# nrf7140_wificore register map
Vendor: Nordic Semiconductor; Series: nRF71; File version: 1
Registers are 32-bit, read-write, reset 0x0 unless marked. A register's access mark holds for its fields unless they carry their own. Offsets are from the block's base; [hi:lo] are bit positions; lines under a group give offsets from that group; {n}, {i} and the like mark numbered series; 'fields as' and 'values as' point back to an identical list.

## RPUPHY (part 8 of 8) — WIFICore RPU PHY peripherals
Base 0x48080000; alternate view of RPUMAC
0x14000 WLAN_RXP group — Unspecified
  0x00 RESET — WLAN RXP RESET
    [2] WLANRXPSTATSCOUNTERSRESET — Self-clearing software reset for the statistics counters.
    [1] WLANRXPLATCHEDSOFTWARERESET — Latched software reset.
    [0] WLANRXPPULSEDSOFTWARERESET — Self-clearing software reset.
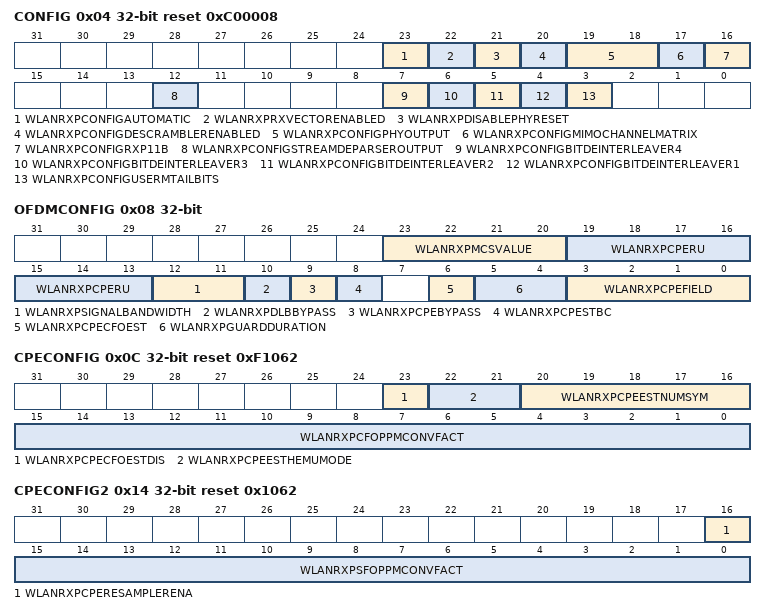
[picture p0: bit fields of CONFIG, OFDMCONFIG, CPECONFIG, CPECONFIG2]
  0x04 CONFIG reset 0xC00008 — WLAN RXP CONFIG
    [23] WLANRXPCONFIGAUTOMATIC — Enable automatic configuration of the RXP.
      0=Manual configuration mode; 1=Automatic configuration mode
    [22] WLANRXPRXVECTORENABLED — Enable Rx-vector generation.
      0=Rx-vector not generated; 1=Rx-vector is sent before the decoded data
    [21] WLANRXPDISABLEPHYRESET — Disable automatic PHY reset.
      0=PHY will automatically reset; 1=PHY will not automatically reset
    [20] WLANRXPCONFIGDESCRAMBLERENABLED — Enable descrambler.
      0=BypassDescrambler; 1=EnableDescrambler
    [19:18] WLANRXPCONFIGPHYOUTPUT — Select PHY output.
      0=Viterbi decoder (1 encoder stream, chain 1); 1=ViterbiDecoder1Enco1 (Viterbi decoder (1 encoder stream, chain 2)); 2=Viterbi decoder (2 encoder streams); 3=LdpcDecoder
    [17] WLANRXPCONFIGMIMOCHANNELMATRIX — Select MIMO decoder channel matrix TBus write port destination.
      0=MimoDecoder; 1=LdpcDecoder
    [16] WLANRXPCONFIGRXP11B — Select 802.11b RX demodulator.
      0=OfdmDemodulator; 1=80211BDemodulator
    [12] WLANRXPCONFIGSTREAMDEPARSEROUTPUT — Route first stream deparser output stream to either TBus port or LDPC block formation unit.
      0=Route output data to TBus port; 1=Route output data to LDPC block formation unit
    [7] WLANRXPCONFIGBITDEINTERLEAVER4 — Configure bit de-interleaver for fourth spatial stream.
      0=Bypass bit de-interleaver; 1=UseBitDeInterleaver
    [6] WLANRXPCONFIGBITDEINTERLEAVER3 — Configure bit de-interleaver for third spatial stream.
      0=Bypass bit de-interleaver; 1=UseBitDeInterleaver
    [5] WLANRXPCONFIGBITDEINTERLEAVER2 — Configure bit de-interleaver for second spatial stream.
      0=Bypass bit de-interleaver; 1=UseBitDeInterleaver
    [4] WLANRXPCONFIGBITDEINTERLEAVER1 — Configure bit de-interleaver for first spatial stream.
      0=Bypass bit de-interleaver; 1=UseBitDeInterleaver
    [3] WLANRXPCONFIGUSERMTAILBITS — Configure the removal of tail bits at the output of the Viterbi
      0=NeverRemoveTailBits; 1=Remove tail bits at the output of Viterbi during DATA decoding (cfg_dec_field = 0)
  0x08 OFDMCONFIG — WLAN RXP OFDM CONFIG
    [23:20] WLANRXPMCSVALUE — Modulation and coding scheme
    [19:13] WLANRXPCPERU — HE resource unit allocation for CPE module
    [12:11] WLANRXPSIGNALBANDWIDTH — Selects the signal bandwidth0 : 20MHz1 : 40MHz2 : 80MHz3 : reservedMust be equal or less than CHANNEL_BANDWIDTH.For receive, see the OPERATING_WINDOW description.For transmit, when signal bandwidth is less than channel bandwidth, input OFDM symbol will be duplicatedbefore performing inverse FFT. If channel bandwidth is two times signal bandwidth then OFDM symbol will beduplicated and if channel bandwidth is four times signal bandwidth then OFDM symbol will be quadrupled.
    [10] WLANRXPDLBBYPASS — Delay buffer bypass
      0=DlbEnabled; 1=DlbBypassed
    [9] WLANRXPCPEBYPASS — CPE compensation control.0 : CPE compensation1 : BypassThis field is used when REMOVE_SUB_CARRIERS is active (RX mode).In both cases pilots will be discarded but when bypass is not activeCPE compensation will be performed.
    [8] WLANRXPCPESTBC — Selects STBC mode. HT-packets only.
      0=NonStbc; 1=Stbc
    [6] WLANRXPCPECFOEST — When set enables the CFO estimation based on the CPE.
    [5:4] WLANRXPGUARDDURATION — Specifies the guard duration to be inserted or removed:
      0=04Us; 1=08Us; 2=16Us; 3=32Us
    [3:0] WLANRXPCPEFIELD — Selects packet type:0: LSIG (L)1: LDATA (L)2: HTSIG (L)3: HTDATA (HT)4: VHTSIGA (L)5: VHTSIGB (HT)6: VHTDATA (VHT)7: RLSIG (L)8: HESIGA_SU (HT)9: HESIGA_X (HT)10 : HESIGA_ER (HT)11 : HESIGA_MU (HT)12 : HESIGB (VHT)13 : HEDATA_SU (HE)14 : HEDATA_ER (HE)15 : HEDATA_MU (HE)Packet types 0-3 (Legacy, HT_MF, HT_GF, VHT) are in Pre-HE group with OFDM symbol length of 3.2us.HE packet has 12.8us OFDM symbol length.NOTE: Whenever field is configured the initial state of scrambler will be set accordingly.Scrambler is used within CPE block to generate PN sequence for pilot sign generation. PN sequencehas 127 elements and cyclically repeats after 127 OFDM symbols.
  0x0C CPECONFIG reset 0xF1062 — WLAN RXP CPE CONFIG
    [23] WLANRXPCPECFOESTDIS — Disable the CFO estimation based on the CPE : ignore RXP_CPE_CFO_EST field
    [22:21] WLANRXPCPEESTHEMUMODE — CPE based frequency offset estimation mode for HE-MU packets:
      0=Use HE-SIG-B and Data symbols CPE estimations (final HE-SIG-B in ppm is sum to the Data ppm estimations); 1=Use HE-SIG-B symbols CPE estimations only; 2=Use Data symbols CPE estimations only (if there is only one data Symbol then the HE-SIG-B is used)
    [20:16] WLANRXPCPEESTNUMSYM — Number of CPE estimations used for the CPE based frequency offset estimation.
    [15:0] WLANRXPCFOPPMCONVFACT — Carrier Frequency Offset, to PPM conversion factor: value of OpBW/fc,where OpBw is the operating bandwidth and fc is the channel centre frequency. (u-4.20)Note: default value set for OpBW = 20MHz and fc = 5GHz
  0x10 CPESTATUS ro — WLAN RXP CPE STATUS
    [15:0] WLANRXPCPEFREQUENCYOFFSET — CPE based frequency offset estimation (s-5.20).
  0x14 CPECONFIG2 reset 0x1062 — WLAN RXP CPE CONFIG 2
    [16] WLANRXPCPERESAMPLERENA — Enable CPE estimation based SFO error update to the SCP resampler.
    [15:0] WLANRXPSFOPPMCONVFACT — Sampling Frequency Offset, time tracking conversion factor: value of [resampler factor] * OpBW/fc,where OpBw is the operating bandwidth and fc is the channel centre frequency. (u-4.20)Note: default value set for resampler factor = 1, OpBW = 20MHz and fc = 5GHz
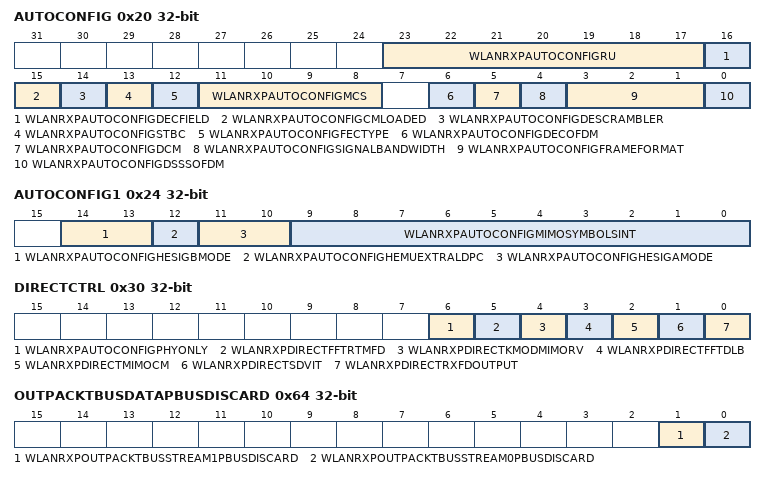
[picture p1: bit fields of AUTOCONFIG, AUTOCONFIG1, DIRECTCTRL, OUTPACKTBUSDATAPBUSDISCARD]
  0x20 AUTOCONFIG — WLAN RXP AUTO CONFIG
    [23:17] WLANRXPAUTOCONFIGRU — HE resource unit allocation
    [16] WLANRXPAUTOCONFIGDECFIELD — Identifies the type of field to be decoded
      0=Data - decoded data sent to EDC; 1=Header - decoded data sent to receiver training mode
    [15] WLANRXPAUTOCONFIGCMLOADED — Assume channel matrices are already loaded into the MIMO decoder
      0=Don't assume channel matrices have been loaded; 1=Assume channel matrices have been loaded
    [14] WLANRXPAUTOCONFIGDESCRAMBLER — Descrambler mode
      0=DescramblerDisabled; 1=DescramblerEnabled
    [13] WLANRXPAUTOCONFIGSTBC — STBC mode
      0=StbcModeDisabled; 1=StbcModeEnabled
    [12] WLANRXPAUTOCONFIGFECTYPE — FEC type
      0=Bcc; 1=Ldpc
    [11:8] WLANRXPAUTOCONFIGMCS — MCSLegacy-0: BPSK rate 1/2Legacy-1: BPSK rate 3/4Legacy-2: QPSK rate 1/2Legacy-3: QPSK rate 3/4Legacy-4: 16-QAM rate 1/2Legacy-5: 16-QAM rate 3/4Legacy-6: 64-QAM rate 2/3Legacy-7: 64-QAM rate 3/4HT-0: BPSK rate 1/2HT-1: QPSK rate 1/2HT-2: QPSK rate 3/4HT-3: 16-QAM rate 1/2HT-4: 16-QAM rate 3/4HT-5: 64-QAM rate 2/3HT-6: 64-QAM rate 3/4HT-7: 64-QAM rate 5/6VHT-0: BPSK rate 1/2VHT-1: QPSK rate 1/2VHT-2: QPSK rate 3/4VHT-3: 16-QAM rate 1/2VHT-4: 16-QAM rate 3/4VHT-5: 64-QAM rate 2/3VHT-6: 64-QAM rate 3/4VHT-7: 64-QAM rate 5/6VHT-8: 256-QAM rate 3/4VHT-9: 256-QAM rate 5/6HE-0: BPSK rate 1/2HE-1: QPSK rate 1/2HE-2: QPSK rate 3/4HE-3: 16-QAM rate 1/2HE-4: 16-QAM rate 3/4HE-5: 64-QAM rate 2/3HE-6: 64-QAM rate 3/4HE-7: 64-QAM rate 5/6HE-8: 256-QAM rate 3/4HE-9: 256-QAM rate 5/6HE-10: 1024-QAM rate 3/4HE-11: 1024-QAM rate 5/6
    [6] WLANRXPAUTOCONFIGDECOFDM — Decode OFDM data (output MUX selection)
      0=OutputDsss11BData; 1=OutputOfdmData
    [5] WLANRXPAUTOCONFIGDCM — Dual carrier modulation
      0=DcmDisabled; 1=DcmEnabled
    [4] WLANRXPAUTOCONFIGSIGNALBANDWIDTH — Signal bandwidth
      0=20Mhz; 1=40Mhz
    [3:1] WLANRXPAUTOCONFIGFRAMEFORMAT — Frame format
      0=Legacy; 1=HtMf; 2=HtGf; 3=HeTb; 4=HeSu; 5=HeMu; 6=HeEr
    [0] WLANRXPAUTOCONFIGDSSSOFDM — DSSS or OFDM
      0=Dsss; 1=Ofdm
  0x24 AUTOCONFIG1 — WLAN RXP AUTO CONFIG 1
    [14:13] WLANRXPAUTOCONFIGHESIGBMODE — Indicates if HE-SIG-B is being decoded and its format:
      0=NormalVhtPacket; 1=HE-SIG-B uncompressed 20/40 MHz ppduBW (18-bit common field, 52-bit User block field); 2=HeSigBUncompressed2 (HE-SIG-B uncompressed 80 MHz ppduBw (27-bit common field,52-bit User block field)); 3=HE-SIG-B compressed (no common field, 52-bit User block field)
    [12] WLANRXPAUTOCONFIGHEMUEXTRALDPC — Force LDPC extra segment flag for decoder configuration for HE-MU packet decoding.
    [11:10] WLANRXPAUTOCONFIGHESIGAMODE — Determines the state of HE-SIGA decoding, used in the LLR combining process
      0=HE-SU - Default state, assumes packet is HE-SU (or any non-HE packet), but may be determined as non HE-SU after decoding LSIG; 1=X - Intermediate state before determining packet is either HE-MU or HE-ER; 2=HE-MU - Packet determined as HE-MU; 3=HE-ER - Packet determined as HE-ER
    [9:0] WLANRXPAUTOCONFIGMIMOSYMBOLSINT — Number of OFDM symbols for which the channel matrices are valid for the MIMO decoder. When this register is set to zero, the channel matrices will never be invalidated.
  0x28 AUTOCONFIG2 — WLAN RXP AUTO CONFIG 2
    [23:0] WLANRXPAUTOCONFIGNUMCODEDBITS — Number of coded bits.For BCC this is per encoded stream and includes service and tail bits.For LDPC this includes service bits.
  0x2C AUTOCONFIG3 — WLAN RXP AUTO CONFIG 3
    [23:0] WLANRXPAUTOCONFIGNUMOFDMSYM — Number of OFDM symbols.Only used in BCC mode.When non-zero, the RXP output packer flushes LLRs to the Viterbi decoder at the end of the last OFDM symbol.
  0x30 DIRECTCTRL — WLAN RXP DIRECT CTRL
    [6] WLANRXPAUTOCONFIGPHYONLY — Defines auto-configuration for WLAN_RXP_DIRECT_RXFD_OUTPUT:
      0=RXP output goes to next pipeline stage (i.e. MAC).; 1=RXP output goes to EDC (tbus)
    [5] WLANRXPDIRECTFFTRTMFD — Selects direct or EDC (tbus) connections.
      0=Tbus; 1=Direct
    [4] WLANRXPDIRECTKMODMIMORV — Selects direct or EDC (tbus) connections.
      0=Tbus; 1=Direct
    [3] WLANRXPDIRECTFFTDLB — Selects direct or EDC (tbus) connections.
      0=Tbus; 1=Direct
    [2] WLANRXPDIRECTMIMOCM — Selects direct or EDC (tbus) connections.
      0=Tbus; 1=Direct
    [1] WLANRXPDIRECTSDVIT — Selects direct or EDC (tbus) connections.
      0=Tbus; 1=Direct
    [0] WLANRXPDIRECTRXFDOUTPUT — Selects whether TXP input comes from previous pipeline stage or EDC (tbus).
      0=Tbus; 1=Direct
  0x34 AUTOCONFIG4 — WLAN RXP AUTO CONFIG 4
    [12:0] WLANRXPAUTOCONFIGHENCBPSLAST — Number of coded bits per symbols in the last pair of OFDM symbols for HE and STBC.
  0x50 STATSCOUNTER0 — WLAN RXP STATS COUNTER 0
    [23:0] WLANRXPGENERATEDEOPCOUNT — Number of decoded packets based on the EOP flag.
  0x64 OUTPACKTBUSDATAPBUSDISCARD — WLAN RXP OUTPACK TBUS DATA PBUS DISCARD
    [1] WLANRXPOUTPACKTBUSSTREAM1PBUSDISCARD — Set this register to '1' to discard the output from the T-Bus Read component that routes data from the stream 1 path to the T-Bus.
    [0] WLANRXPOUTPACKTBUSSTREAM0PBUSDISCARD — Set this register to '1' to discard the output from the T-Bus Read component that routes data from the stream 0 path to the T-Bus.
  {0x70+4j} CPECHSTREAM1PILOT[{j}] (j=0..7) — Description collection: WLAN RXP CPE CH STREAM1 PILOT
    [23:0] WLANCPECHSTREAM1PILOT — Channel estimate for stream 1 on the pilot subcarrier.
  {0x90+4j} CPECHSTREAM2PILOT[{j}] (j=0..7) — Description collection: WLAN RXP CPE CH STREAM2 PILOT
    [23:0] WLANCPECHSTREAM2PILOT — Channel estimate for stream 2 on the pilot subcarrier.
  0xB4 WLANRXFDDEBUG
    [1:0] WLANRXFDDEBUG — Enable debug registers WLAN_RXFD_DEBUG_VALID and WLAN_RXFD_DEBUG_ENABLE
      0=Disabled; 1=ValidEnable; 2=Sticky(Valid), Sticky(Enable); 3=Valid & Enable, Sticky(Valid & Enable)
  0xB8 WLANRXFDDEBUGVALID ro
    [31:0] WLANRXFDDEBUGVALID — Live state of the valid flow control signals0: DBL Input1: DLB Output2: CPE/KMOD Input3: CPE/KMOD Output4: MIMO RV Input5: MIMO CM Input6: MIMO Output7: DCM Input8: DCM Output9: BDI Input10: BDI Output11: LLR Combining BDI Input12: LLR Combining DCM Input13: LLR Combining Output14: Deparser Input15: Deparser Output16: OutputPacker Input17: OutputPacker Output18: Viterbi Input19: Viterbi Output20: LDPC Input21: LDPC Output22: Descramler Input23: Descrambler Output24: Error Mask Input25: Error Mask Output26: RTM FD FFT Raw Input27: RTM FD Dec Input28: RTM FD RXV Output29: RTM FD BMF Output30: RTM FD RTM CM Output31: RTM FD CHE Output
  0xBC WLANRXFDDEBUGENABLE ro
    [31:0] WLANRXFDDEBUGENABLE — Live state of the enable flow control signals0: DBL Input1: DLB Output2: CPE/KMOD Input3: CPE/KMOD Output4: MIMO RV Input5: MIMO CM Input6: MIMO Output7: DCM Input8: DCM Output9: BDI Input10: BDI Output11: LLR Combining BDI Input12: LLR Combining DCM Input13: LLR Combining Output14: Deparser Input15: Deparser Output16: OutputPacker Input17: OutputPacker Output18: Viterbi Input19: Viterbi Output20: LDPC Input21: LDPC Output22: Descramler Input23: Descrambler Output24: Error Mask Input25: Error Mask Output26: RTM FD FFT Raw Input27: RTM FD Dec Input28: RTM FD RXV Output29: RTM FD BMF Output30: RTM FD RTM CM Output31: RTM FD CHE Output
0x15000 WLAN_RXP_11B group — Unspecified
  0x00 RESET — WLAN RXP 11B RESET
    [2] WLANRXP11BSTATSCOUNTERSRESET — Self-clearing software reset for the statistics counters.
    [1] WLANRXP11BLATCHEDSOFTWARERESET — Latched software reset.
    [0] WLANRXP11BPULSEDSOFTWARERESET — Self-clearing software reset.
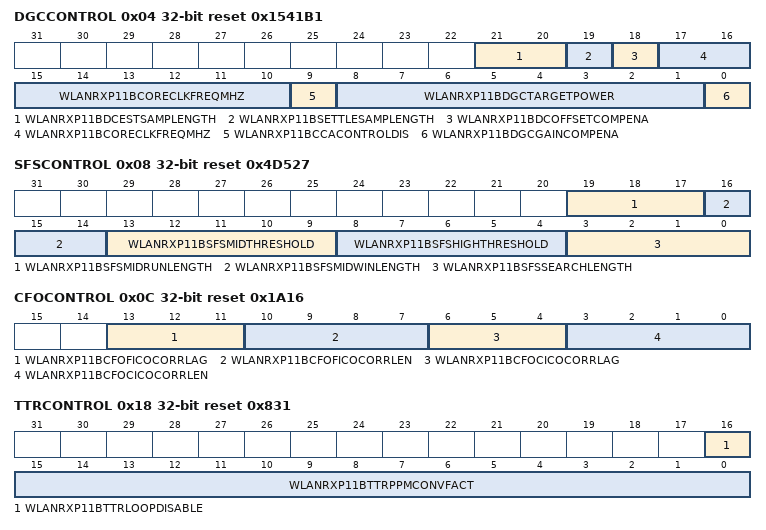
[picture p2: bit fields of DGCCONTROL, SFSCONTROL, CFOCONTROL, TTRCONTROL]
  0x04 DGCCONTROL reset 0x1541B1 — WLAN RXP 11B DGC CONTROL
    [21:20] WLANRXP11BDCESTSAMPLENGTH — Number of samples used for DC estimation:
      0=44Samples; 1=88Samples; 2=132Samples; 3=176Samples
    [19] WLANRXP11BSETTLESAMPLENGTH — Number of samples for datapath settling before DC estimation starts:
      0=22Samples; 1=44Samples
    [18] WLANRXP11BDCOFFSETCOMPENA — Enable/disable DC offset compensation.
    [17:10] WLANRXP11BCORECLKFREQMHZ — Core clock frequency in MHz. (u8.0)
    [9] WLANRXP11BCCACONTROLDIS — Disable / enable CCA control for correlation indication and status known (ED).Timer non-zero flag always zero when disabled.
    [8:1] WLANRXP11BDGCTARGETPOWER — Target power for the compensation factor calculation (s5.2).
    [0] WLANRXP11BDGCGAINCOMPENA — Enable/disable gain compensation.
  0x08 SFSCONTROL reset 0x4D527 — WLAN RXP 11B SFS CONTROL
    [19:17] WLANRXP11BSFSMIDRUNLENGTH — Mid-threshold peak detection run length (u3.0). Valid range is 2 to WLAN_RXP_11B_SFS_MID_WIN_LENGTH.
    [16:14] WLANRXP11BSFSMIDWINLENGTH — Mid-threshold peak detection window length (u3.0). Valid range is 2 to 7.
    [13:9] WLANRXP11BSFSMIDTHRESHOLD — Correlation mid-threshold factor (u2.3).
    [8:4] WLANRXP11BSFSHIGHTHRESHOLD — Correlation high-threshold factor (u2.3).
    [3:0] WLANRXP11BSFSSEARCHLENGTH — Maximum number of symbols checked for the fine synchronisation. Valid range is 1 to 15.
  0x0C CFOCONTROL reset 0x1A16 — WLAN RXP 11B CFO CONTROL
    [13:11] WLANRXP11BCFOFICOCORRLAG — Initial fine estimation correlation lag (u4.0). Valid range is 1 to 4.
    [10:7] WLANRXP11BCFOFICOCORRLEN — Initial fine estimation correlation length (u4.0). Valid range is 1 to 15.
    [6:4] WLANRXP11BCFOCICOCORRLAG — Initial coarse estimation correlation lag (u4.0). Valid range is 1 to 4.
    [3:0] WLANRXP11BCFOCICOCORRLEN — Initial coarse estimation correlation length (u4.0). Valid range is 1 to 15.
  0x10 CFOSTATUS0 ro — WLAN RXP 11B CFO STATUS 0
    [15:0] WLANRXP11BCFOCICOOFFSET — Coarse intial frequency-offset estimation (s-2.17).
  0x14 CFOSTATUS1 ro — WLAN RXP 11B CFO STATUS 1
    [15:0] WLANRXP11BCFOFICOOFFSET — Fine initial frequency-offset estimation (s-2.17).
  0x18 TTRCONTROL reset 0x831 — WLAN RXP 11B TTR CONTROL
    [16] WLANRXP11BTTRLOOPDISABLE — Disable/enable time tracking - resampler loop.
    [15:0] WLANRXP11BTTRPPMCONVFACT — Time tracking conversion factor: value of [resampler factor] * fs/fc programmed by MAC (u-4.20).
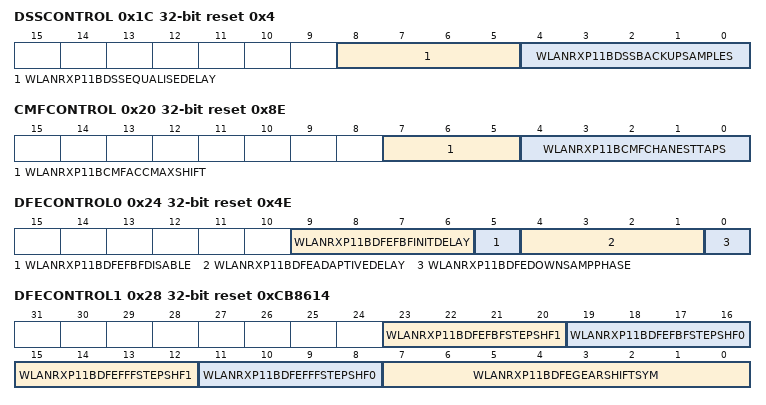
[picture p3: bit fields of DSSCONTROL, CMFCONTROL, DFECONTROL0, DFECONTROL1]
  0x1C DSSCONTROL reset 0x4 — WLAN RXP 11B DSS CONTROL
    [8:5] WLANRXP11BDSSEQUALISEDELAY — Number of delay symbols for the decision-feedback equaliser after start of the CMF (u4.0).
    [4:0] WLANRXP11BDSSBACKUPSAMPLES — Number of backup samples refered to the strongest path location (u5.0). Valid range is 1 to 21.
  0x20 CMFCONTROL reset 0x8E — WLAN RXP 11B CMF CONTROL
    [7:5] WLANRXP11BCMFACCMAXSHIFT — Defines the maximum shift in the channel estimation average (u3.0). Valid range is 1 to 5.
    [4:0] WLANRXP11BCMFCHANESTTAPS — Number of channel estimated taps used in the channel matching filter (u5.0). Valid range is 1 to 22.
  0x24 DFECONTROL0 reset 0x4E — WLAN RXP 11B DFE CONTROL 0
    [9:6] WLANRXP11BDFEFBFINITDELAY — Feed-back filter start delay after start of the equaliser (u4.0). Only applies when WLAN_RXP_11B_DFE_FBF_DISABLE is 0. Valid range is 1 to 15.
    [5] WLANRXP11BDFEFBFDISABLE — Disable/enable the feed-back filter.
    [4:1] WLANRXP11BDFEADAPTIVEDELAY — Phase reference chip delay for the equaliser training (u4.0). Valid range is 3 to 10 when WLAN_RXP_11B_DFE_DOWNSAMP_PHASE = 0, 3 to 9 otherwise.
    [0] WLANRXP11BDFEDOWNSAMPPHASE — Feed-forward filter down-sampling phase, 0 or 1.
  0x28 DFECONTROL1 reset 0xCB8614 — WLAN RXP 11B DFE CONTROL 1
    [23:20] WLANRXP11BDFEFBFSTEPSHF1 — LMS step size shift after gear-shift for the feed-back filter (u4.0). Step = 1>>WLAN_RXP_11B_DFE_FBF_STEP_SHF_1.
    [19:16] WLANRXP11BDFEFBFSTEPSHF0 — LMS step size shift before gear-shift for the feed-back filter (u4.0). Step = 1>>WLAN_RXP_11B_DFE_FBF_STEP_SHF_0.
    [15:12] WLANRXP11BDFEFFFSTEPSHF1 — LMS step size shift after gear-shift for the feed-forward filter (u4.0). Step = 1>>WLAN_RXP_11B_DFE_FFF_STEP_SHF_1.
    [11:8] WLANRXP11BDFEFFFSTEPSHF0 — LMS step size shift before gear-shift for the feed-forward filter (u4.0). Step = 1>>WLAN_RXP_11B_DFE_FFF_STEP_SHF_0.
    [7:0] WLANRXP11BDFEGEARSHIFTSYM — Number of symbols at which equaliser gear-shift happens (u8.0).
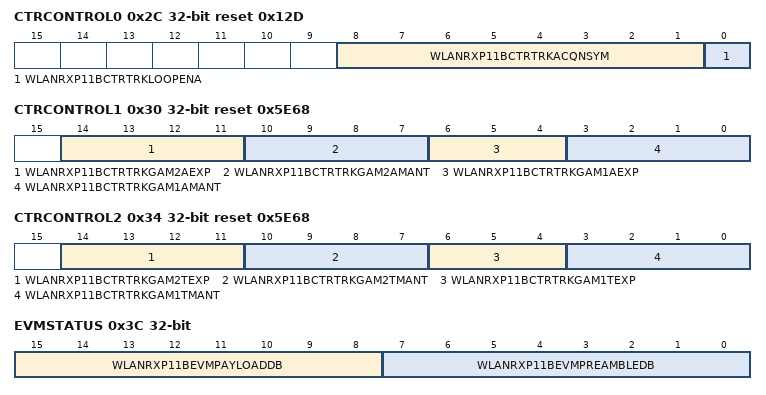
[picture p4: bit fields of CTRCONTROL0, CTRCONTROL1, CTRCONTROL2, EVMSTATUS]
  0x2C CTRCONTROL0 reset 0x12D — WLAN RXP 11B CTR CONTROL 0
    [8:1] WLANRXP11BCTRTRKACQNSYM — Number of symbols in the acquisition phase (u8.0). Valid range is 1 to 255.
    [0] WLANRXP11BCTRTRKLOOPENA — Enable/disable the carrier tracking loop.
  0x30 CTRCONTROL1 reset 0x5E68 — WLAN RXP 11B CTR CONTROL 1
    [14:11] WLANRXP11BCTRTRKGAM2AEXP — Gamma2-exponent loop filter gain for the acquisition phase (u4.0).
    [10:7] WLANRXP11BCTRTRKGAM2AMANT — Gamma2-mantissa loop filter gain for the acquisition phase (u0.4).
    [6:4] WLANRXP11BCTRTRKGAM1AEXP — Gamma1-exponent loop filter gain for the acquisition phase (u3.0).
    [3:0] WLANRXP11BCTRTRKGAM1AMANT — Gamma1-mantissa loop filter gain for the acquisition phase (u0.4).
  0x34 CTRCONTROL2 reset 0x5E68 — WLAN RXP 11B CTR CONTROL 2
    [14:11] WLANRXP11BCTRTRKGAM2TEXP — Gamma2-exponent loop filter gain for the tracking phase (u4.0).
    [10:7] WLANRXP11BCTRTRKGAM2TMANT — Gamma2-mantissa loop filter gain for the tracking phase (u0.4).
    [6:4] WLANRXP11BCTRTRKGAM1TEXP — Gamma1-exponent loop filter gain for the tracking phase (u3.0).
    [3:0] WLANRXP11BCTRTRKGAM1TMANT — Gamma1-mantissa loop filter gain for the tracking phase (u0.4).
  0x38 CTRSTATUS ro — WLAN RXP 11B CTR STATUS
    [17:0] WLANRXP11BCTRTRKFREQERR — Carrier frequency tracking error (s0.17).
  0x3C EVMSTATUS ro — WLAN RXP 11B EVM STATUS
    [15:8] WLANRXP11BEVMPAYLOADDB — Payload EVM measure in dB (s5.2).
    [7:0] WLANRXP11BEVMPREAMBLEDB — Preamble and header EVM measure in dB (s5.2).
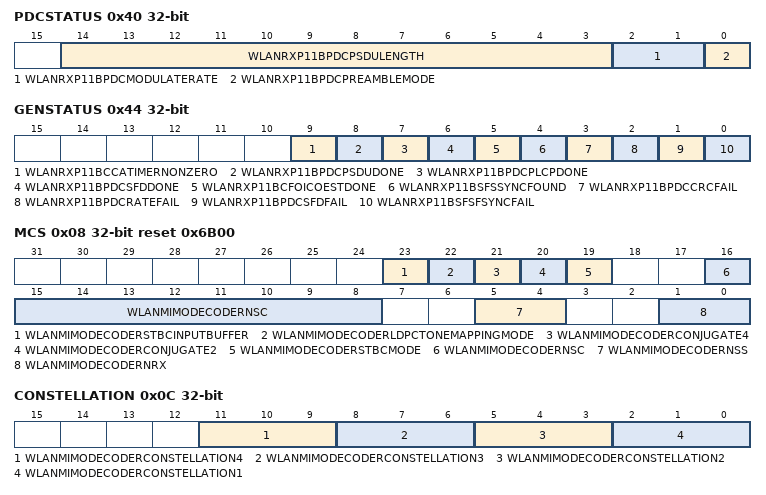
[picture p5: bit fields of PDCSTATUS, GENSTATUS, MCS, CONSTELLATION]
  0x40 PDCSTATUS ro — WLAN RXP 11B PDC STATUS
    [14:3] WLANRXP11BPDCPSDULENGTH — PSDU length in octets (u12.0).
    [2:1] WLANRXP11BPDCMODULATERATE — Modulation rate:
      0=1Mbps; 1=2Mbps; 2=55Mbps; 3=11Mbps
    [0] WLANRXP11BPDCPREAMBLEMODE — Preamble mode:
      0=LongPreable; 1=ShortPreamble
  0x44 GENSTATUS ro — WLAN RXP 11B GEN STATUS
    [9] WLANRXP11BCCATIMERNONZERO — CCA timer non-zero.
    [8] WLANRXP11BPDCPSDUDONE — Indicates PSDU (data) has been processed and decoded.
    [7] WLANRXP11BPDCPLCPDONE — Indicates PLCP (preamble + header) has been processed and decoded.
    [6] WLANRXP11BPDCSFDDONE — Indicates SFD has been detected.
    [5] WLANRXP11BCFOICOESTDONE — Indicates both coarse and fine carrier offset estimations are completed.
    [4] WLANRXP11BSFSSYNCFOUND — Indicates symbol synchronisation is found.
    [3] WLANRXP11BPDCCRCFAIL — Indicates PLCP header CRC check failure.
    [2] WLANRXP11BPDCRATEFAIL — Indicates header rate decoding failure.
    [1] WLANRXP11BPDCSFDFAIL — Indicates SFD detection failure.
    [0] WLANRXP11BSFSFSYNCFAIL — Indicates symbol synchronisation failure.
  0x48 GENCONTROL — WLAN RXP 11B GEN CONTROL
    [0] WLANRXP11BGENERATEEOP — Generate an EOP flag at the end of the packet:
      0=Don't generate an EOP flag at the end of the packet; 1=Generate an EOP flag at the end of the packet
  0x4C STATSCOUNTER0 — WLAN RXP 11B STATS COUNTER 0
    [23:0] WLANRXP11BCORRELATIONPASSCOUNT — Number of detected DSSS packets.
  0x50 STATSCOUNTER1 — WLAN RXP 11B STATS COUNTER 1
    [23:0] WLANRXP11BFSYNCFAILCOUNT — Number of DSSS packets failed to synchronise - SFS.Note: write zeros to 'software reset' this register.
  0x54 STATSCOUNTER2 — WLAN RXP 11B STATS COUNTER 2
    [23:0] WLANRXP11BSFDFAILCOUNT — Number of DSSS packets failed SFD detection.
  0x58 STATSCOUNTER3 — WLAN RXP 11B STATS COUNTER 3
    [23:0] WLANRXP11BHEADERFAILCOUNT — Number of DSSS packets failed header checks - CRC or other conditions.Note: write zeros to 'software reset' this register.
  0x5C CONFIG ro reset 0x1 — WLAN RXP 11B CONFIG
    [0] WLANRXP11BCCKSUPPORT — Indicates CCK modulation support in the RXP-11b pipeline:
      0=DsssModulationOnly; 1=CckDsssModulations
0x16000 WLAN_MIMO_DECODER group — Unspecified
  0x00 CAPABILITIES ro reset 0x6B00 — WLAN MIMO DECODER CAPABILITIES
    [16:8] WLANMIMODECODERMAXSC — Maximum supported sub-carriers per OFDM symbol (N_SC).Note that the number of sub-carriers is returned '-1'.
    [5:4] WLANMIMODECODERMAXSS — Maximum supported spatial streams (N_SS).Note that the number of spatial streams is returned '-1'.
    [1:0] WLANMIMODECODERMAXRX — Maximum supported receive chains (N_RX).Note that the number of receive chains is returned '-1'.
  0x04 RESET — WLAN MIMO DECODER RESET
    [1] WLANMIMODECODERLATCHEDSOFTWARERESET — Latched software reset.
    [0] WLANMIMODECODERPULSEDSOFTWARERESET — Self-clearing software reset.
  0x08 MCS reset 0x6B00 — WLAN MIMO DECODER MCS
    [23] WLANMIMODECODERSTBCINPUTBUFFER — Enable STBC input buffer.
      0=STBC input buffer disabled; 1=STBC input buffer enabled
    [22] WLANMIMODECODERLDPCTONEMAPPINGMODE — Enable LDPC Tone Mapping mode.
      0=LDPC Tone Mapping mode disabled; 1=LDPC Tone Mapping mode enabled
    [21] WLANMIMODECODERCONJUGATE4 — Conjugate fourth spatial stream.
      0=ConjugationDisabled; 1=ConjugationEnabled
    [20] WLANMIMODECODERCONJUGATE2 — Conjugate second spatial stream.
      0=ConjugationDisabled; 1=ConjugationEnabled
    [19] WLANMIMODECODERSTBCMODE — Enable STBC mode (only applicable when N_RX=1).
      0=StbcModeDisabled; 1=StbcModeEnabled
    [16:8] WLANMIMODECODERNSC — Number of sub-carriers per OFDM symbol (N_SC).Note that the number of sub-carriers is stored '-1', therefore the default of 107 corresponds to N_SC=108.The MIMO decoder supports N_SC468 is reserved.A software reset must be performed before changing N_SC.
    [5:4] WLANMIMODECODERNSS — Number of spatial streams (N_SS).Note that the number of spatial streams is stored '-1'.
    [1:0] WLANMIMODECODERNRX — Number of receive chains (N_RX).Note that the number of receive chains is stored '-1'.
  0x0C CONSTELLATION — WLAN MIMO DECODER CONSTELLATION
    [all] fields
      0=Bpsk; 1=Qpsk; 2=16Qam; 3=64Qam; 4=256Qam; 5=Reserve (This is reserved.); 6=Reserve6 (This is reserved.); 7=Reserve7 (This is reserved.)
    [11:9] WLANMIMODECODERCONSTELLATION4 — Constellation type for fourth spatial stream.
    [8:6] WLANMIMODECODERCONSTELLATION3 — Constellation type for third spatial stream.
    [5:3] WLANMIMODECODERCONSTELLATION2 — Constellation type for second spatial stream.
    [2:0] WLANMIMODECODERCONSTELLATION1 — Constellation type for first spatial stream.
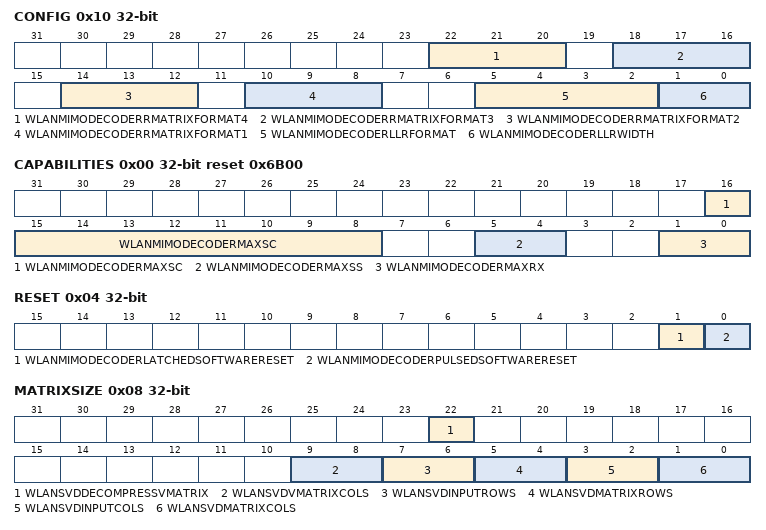
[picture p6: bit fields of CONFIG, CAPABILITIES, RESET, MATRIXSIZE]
  0x10 CONFIG — WLAN MIMO DECODER CONFIG
    [22:20] WLANMIMODECODERRMATRIXFORMAT4 — Specify the number of LSBs to drop from each R-matrix element for fourth spatial stream.Note that only settings of 0-4 are supported.5-7 are reserved.
    [18:16] WLANMIMODECODERRMATRIXFORMAT3 — Specify the number of LSBs to drop from each R-matrix element for third spatial stream.Note that only settings of 0-4 are supported.5-7 are reserved.
    [14:12] WLANMIMODECODERRMATRIXFORMAT2 — Specify the number of LSBs to drop from each R-matrix element for second spatial stream.Note that only settings of 0-4 are supported.5-7 are reserved.
    [10:8] WLANMIMODECODERRMATRIXFORMAT1 — Specify the number of LSBs to drop from each R-matrix element for first spatial stream.Note that only settings of 0-4 are supported.5-7 are reserved.
    [5:2] WLANMIMODECODERLLRFORMAT — For fixed point LLRs, specify the number of LSBs to truncate from full precision 16-bit LLRs.For floating point mode, specify the number of fractional bits we assume the full precision 16-bit LLRs represent.
    [1:0] WLANMIMODECODERLLRWIDTH — Select LLR bit width.
      0=4-bit fixed point, suitable for Viterbi decoder input, where LLR = log(P(x=1)/P(x=0)); 1=6-bit fixed point, suitable for Viterbi decoder input, where LLR = log(P(x=1)/P(x=0)); 2=8-bit fixed point, suitable for Viterbi decoder input, where LLR = log(P(x=1)/P(x=0)); 3=8BitFixedPointSuit3 (8-bit fixed point, suitable for LDPC decoder Q6.1 input, where LLR = log(P(x=0)/P(x=1)))
  0x14 OFDMSYMBOLS — WLAN MIMO DECODER OFDM SYMBOLS
    [9:0] WLANMIMODECODEROFDMSYMBOLS — Specify the number of OFDM symbols for which the channel matrices are valid.Once the specified number of OFDM symbols have been processed, the channel matrices are invalidated, and a new set of channel matrices will be used.Provided suitable hardware support is enabled, it is possible to pre-load the next set of channel matrices whilst processing receive vectors with the current set of channel matrices.Note that once the current set of channel matrices have been invalidated, no new receive vectors will be processed until the next set of channel matrices have been loaded (or pre-loaded).When this register is set to zero, the channel matrices will never be invalidated, and subsequent channel matrix loads will overwrite existing data in-place.
  0x18 CMLOADED — WLAN MIMO DECODER CM LOADED
    [0] WLANMIMODECODERCMLOADED — Assume channel matrices are already loaded into the MIMO decoder
      values as WLAN_RXP.AUTOCONFIG.WLANRXPAUTOCONFIGCMLOADED
  0x1C LDPCTONEMAPPINGDISTANCE reset 0x4 — WLAN MIMO DECODER LDPC TONE MAPPING DISTANCE
    [3:0] WLANMIMODECODERLDPCTONEMAPPINGDISTANCE — LDPC tone mapping distance: defines the distance of seperation between data tones.
  {0x40+0x1C*j} TBUSRDLLRS{j}MODE (j=1..4) — WLAN MIMO DECODER TBUS RD LLRS {j} MODE
    [1] WLANMIMODECODERTBUSRDLLRS{j}DISCARD — Discard PBus debug mode output (WLAN_MIMO_DECODER_TBUS_RD_LLRS_{j}_MODE=1):
      0=Output to PBus (debug mode); 1=DiscardOutput
  {0x58+0x1C*j} TBUSRDLLRS{j}SIGNATURE ro reset 0xFFFFFF (j=1..4) — WLAN MIMO DECODER TBUS RD LLRS {j} SIGNATURE
    [23:0] WLANMIMODECODERTBUSRDLLRS{j}SIGNATURE — TBus debug LLRs {j} output data signature.
0x17000 WLAN_SVD group — Unspecified
  0x00 CAPABILITIES ro — WLAN SVD CAPABILITIES
    [5:4] WLANSVDMATRIXMAXROWS — Maximum supported matrix rows
      0=1Row; 1=2Rows; 2=3Rows; 3=4Rows
    [1:0] WLANSVDMATRIXMAXCOLS — Maximum supported matrix columns
      0=1Column; 1=2Columns; 2=3Columns; 3=4Columns
  0x04 RESET — WLAN SVD RESET
    [1] WLANSVDLATCHEDSOFTWARERESET — Latched software reset.
    [0] WLANSVDPULSEDSOFTWARERESET — Self-clearing software reset.
  0x08 MATRIXSIZE — WLAN SVD MATRIX SIZE
    [22] WLANSVDDECOMPRESSVMATRIX — Use V-matrix decompression
      0=Don't decompress V-matrix; 1=DecompressVMatrix
    [9:8] WLANSVDVMATRIXCOLS — When using compressed V-matrix representation, select the number of V-matrix columns
      0=1Column; 1=2Columns; 2=3Columns; 3=4Columns
    [7:6] WLANSVDINPUTROWS — Select the number of matrix rows to be loaded
      0=1Row; 1=2Rows; 2=3Rows; 3=4Rows
    [5:4] WLANSVDMATRIXROWS — Select the number of matrix rows
      0=1Row; 1=2Rows; 2=3Rows; 3=4Rows
    [3:2] WLANSVDINPUTCOLS — Select the number of matrix columns to be loaded
      0=1Column; 1=2Columns; 2=3Columns; 3=4Columns
    [1:0] WLANSVDMATRIXCOLS — Select the number of matrix columns
      0=1Column; 1=2Columns; 2=3Columns; 3=4Columns
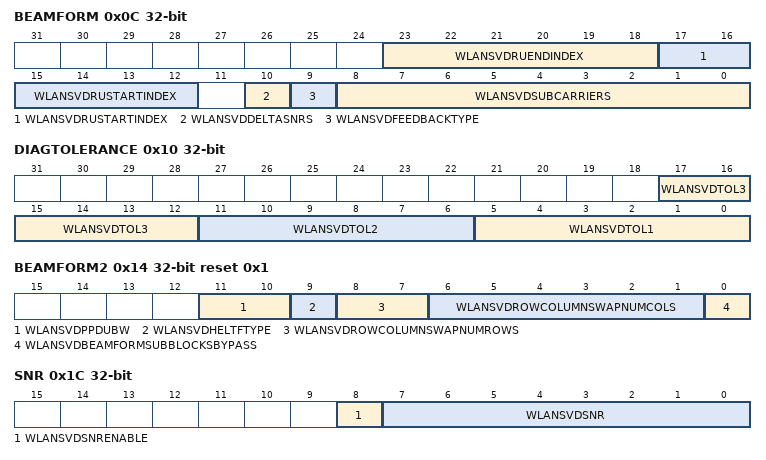
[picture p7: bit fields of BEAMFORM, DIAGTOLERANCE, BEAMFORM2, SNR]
  0x0C BEAMFORM — WLAN SVD BEAMFORM
    [23:18] WLANSVDRUENDINDEX — RU end index for HE-MU0-36: RU end index
    [17:12] WLANSVDRUSTARTINDEX — RU start index for HE-MU0-36: RU start index
    [10] WLANSVDDELTASNRS — Output delta SNR for each sub-carrier
      0=DonTOutputDeltaSnrs; 1=OutputDeltaSnrs
    [9] WLANSVDFEEDBACKTYPE — Beamforming feedback type
      0=SuType; 1=MuType
    [8:0] WLANSVDSUBCARRIERS — Number of sub-carriers used.
  0x10 DIAGTOLERANCE — WLAN SVD DIAG TOLERANCE
    [17:12] WLANSVDTOL3 — Tolerance 3 for diagonalisation stage. Tolerance values are in format Q2.11, the field contains the 6 LSBs.
    [11:6] WLANSVDTOL2 — Tolerance 2 for diagonalisation stage. Tolerance values are in format Q2.11, the field contains the 6 LSBs.
    [5:0] WLANSVDTOL1 — Tolerance 1 for diagonalisation stage. Tolerance values are in format Q2.11, the field contains the 6 LSBs.
  0x14 BEAMFORM2 reset 0x1 — WLAN SVD BEAMFORM 2
    [11:10] WLANSVDPPDUBW — PPDU bandwidth:
      0=20Mhz; 1=40Mhz; 2=80Mhz
    [9] WLANSVDHELTFTYPE — HE-LTF type:
      0=HeLtf4X; 1=HeLtf2X
    [8:7] WLANSVDROWCOLUMNSWAPNUMROWS — Number of rows corresponds to the number of NSTS for which input data is expected:
      1=2Nsts; 2=3Nsts; 3=4Nsts
    [6:1] WLANSVDROWCOLUMNSWAPNUMCOLS — Number of columns corresponds to the number of sub-carriers in each LTF:51: 52 sub-carriers for VHT63: 64 sub-carriers for HE
    [0] WLANSVDBEAMFORMSUBBLOCKSBYPASS — Bypass all beamform sub-blocks (row-column swap, decoupling, cyclic delay removal) :
      0=beamform sub-blocks logic active; 1=BeamformSubBlocksLo1 (beamform sub-blocks logic bypassed)
  0x18 DMALENGTH — WLAN SVD DMA LENGTH
    [8:0] WLANSVDDMALENGTH — Packed angles length in bytes. This length depends on the feedback type (SU or MU),on the number of sub-carriers (52 for VHT and 64 for HE) and on the number of LTFs (2, 3 or 4).For example, the maximum length will be for the case with 4 LTFs, MU type and 64 sub-carriers(6 angles per sub-carrier with length of 9+7+9+7+9+7 = 48 bits -> 64*48/8 = 384 bytes). (.
  0x1C SNR — WLAN SVD SNR
    [8] WLANSVDSNRENABLE — Enable SNR calculation: 0: disabled, 1: enabled.
    [7:0] WLANSVDSNR — One SNR value derived from single sigma value (s[0]) of each sub-carrier.This value will be used by MAC controller to generate compressed beamforming report information.
  0x20 DMALENGTHEFSTATUS ro — WLAN SVD DMA LENGTH EF STATUS
    [0] WLANSVDDMALENGTHEFSTATUS — This flag is set to '1' after the config update from PHY is received and DMA_LENGTH for packed angles is calculated.
  0x24 DMALENGTHEFCLEAR — WLAN SVD DMA LENGTH EF CLEAR
    [0] WLANSVDDMALENGTHEFCLEAR — WLAN_SVD DMA_LENGTH Event Flag Clear
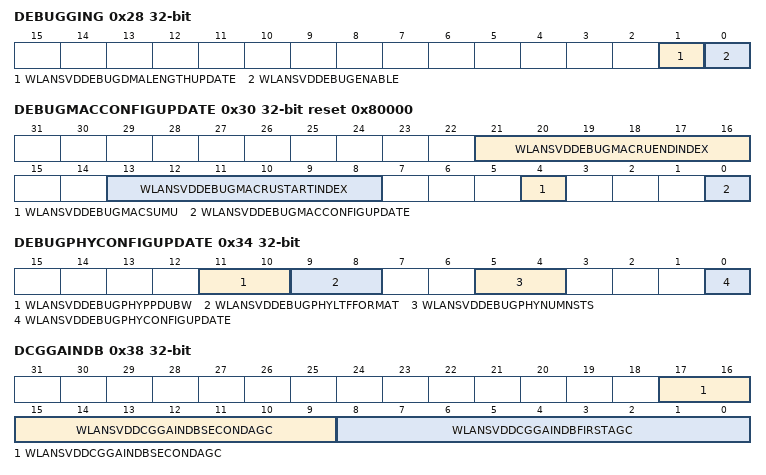
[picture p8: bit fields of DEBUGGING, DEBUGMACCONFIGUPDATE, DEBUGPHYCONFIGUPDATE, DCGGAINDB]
  0x28 DEBUGGING — WLAN SVD DEBUG
    [1] WLANSVDDEBUGDMALENGTHUPDATE — Debug register for dma_length_update input signal.
    [0] WLANSVDDEBUGENABLE — If set to 1, the module will use the debug fields.
  0x2C NOISEPOWER — WLAN SVD NOISE POWER
    [20:0] WLANSVDNOISEPOWER — Linear noise power, u-1.22. Write before PHY_CONFIG_UPDATE register
  0x30 DEBUGMACCONFIGUPDATE reset 0x80000 — WLAN SVD DEBUG MAC CONFIG UPDATE
    [21:16] WLANSVDDEBUGMACRUENDINDEX — Debug register for mac_ru_end_index input signal
    [13:8] WLANSVDDEBUGMACRUSTARTINDEX — Debug register for mac_ru_start_index input signal
    [4] WLANSVDDEBUGMACSUMU — Debug register for mac_su_mu input signal
    [0] WLANSVDDEBUGMACCONFIGUPDATE — Debug register for mac_config_update input signal:
      0=NoAction; 1=Pulse mac_config_update input signal when WLAN_SVD_DEBUG_ENABLE=1
  0x34 DEBUGPHYCONFIGUPDATE — WLAN SVD DEBUG PHY CONFIG UPDATE
    [11:10] WLANSVDDEBUGPHYPPDUBW — Debug register for phy_ppdu_bw input signal
    [9:8] WLANSVDDEBUGPHYLTFFORMAT — Debug register for phy_ltf_format input signal
    [5:4] WLANSVDDEBUGPHYNUMNSTS — Debug register for phy_num_nsts input signal
    [0] WLANSVDDEBUGPHYCONFIGUPDATE — Debug register for phy_config_update input signal:
      0=NoAction; 1=Pulse phy_config_update input signal when WLAN_SVD_DEBUG_ENABLE=1
  0x38 DCGGAINDB — WLAN SVD DCG GAIN DB
    [17:9] WLANSVDDCGGAINDBSECONDAGC — Debug register for DCG gain dB after second AGC (s6.2). Write before PHY_CONFIG_UPDATE register.
    [8:0] WLANSVDDCGGAINDBFIRSTAGC — Debug register for DCG gain dB before second AGC (s6.2). Write before PHY_CONFIG_UPDATE register.
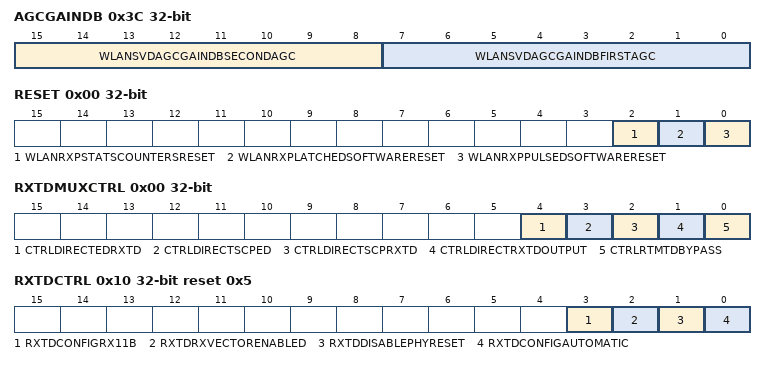
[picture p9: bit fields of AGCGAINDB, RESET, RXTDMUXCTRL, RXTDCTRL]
  0x3C AGCGAINDB — WLAN SVD AGC GAIN DB
    [15:8] WLANSVDAGCGAINDBSECONDAGC — Debug register for AGC gain dB after second AGC (s7.0). Write before PHY_CONFIG_UPDATE register.
    [7:0] WLANSVDAGCGAINDBFIRSTAGC — Debug register for AGC gain dB before second AGC (s7.0). Write before PHY_CONFIG_UPDATE register.
  0x50 TBUSRDMODE — WLAN SVD TBUS RD MODE
    [1] WLANSVDTBUSRDDISCARD — Discard PBus debug mode output (WLAN_SVD_TBUS_RD_MODE=1):
      0=Output to PBus (debug mode); 1=DiscardOutput
  0x5C TBUSRDSIGNATURE ro reset 0xFFFFFF — WLAN SVD TBUS RD SIGNATURE
    [23:0] WLANSVDTBUSRDSIGNATURE — TBus debug S-matrix & V-matrix output data signature.
  0x60 BEAMFORMTBUSRDMODE — WLAN SVD BEAMFORM TBUS RD MODE
    [1] WLANSVDBEAMFORMTBUSRDDISCARD — Discard PBus debug mode output (WLAN_SVD_BEAMFORM_TBUS_RD_MODE=1):
      0=Output to PBus (debug mode); 1=DiscardOutput
  0x6C BEAMFORMTBUSRDSIGNATURE ro reset 0xFFFFFF — WLAN SVD BEAMFORM TBUS RD SIGNATURE
    [23:0] WLANSVDBEAMFORMTBUSRDSIGNATURE — TBus debug Beamforming output data signature.
0x19000 WLAN_LDPC_DECODER group — Unspecified
  0x00 RESET — WLAN LDPC DECODER RESET
    [1] WLANLDPCDECODERLATCHEDSOFTWARERESET — Latched software reset.
    [0] WLANLDPCDECODERPULSEDSOFTWARERESET — Self-clearing software reset.
  0x04 CODE — WLAN LDPC DECODER CODE
    [3:0] WLANLDPCDECODERCODE — Select LDPC code:0: Codeword length 648 rate 1/21: Codeword length 648 rate 2/32: Codeword length 648 rate 3/43: Codeword length 648 rate 5/64: Codeword length 1296 rate 1/25: Codeword length 1296 rate 2/36: Codeword length 1296 rate 3/47: Codeword length 1296 rate 5/68: Codeword length 1944 rate 1/29: Codeword length 1944 rate 2/310: Codeword length 1944 rate 3/411: Codeword length 1944 rate 5/612-15: Reserved
  0x08 ITERATIONS reset 0x5 — WLAN LDPC DECODER ITERATIONS
    [3:0] WLANLDPCDECODERITERATIONS — Number of iterations the decoder performs for each codeword.Note that the valid is stored '-1'.
  0x0C CODEWORDS — WLAN LDPC DECODER CODEWORDS
    [15:0] WLANLDPCDECODERCODEWORDS — Number of codewords in each packet (N_CW).Note that the value is stored '-1'.
  0x10 SHORTENEDBITS — WLAN LDPC DECODER SHORTENED BITS
    [10:0] WLANLDPCDECODERSHORTENEDBITS — Number of shortened bits per codeword.Calculated as floor(N_shrt/N_CW).
  0x14 PUNCTUREDBITS — WLAN LDPC DECODER PUNCTURED BITS
    [9:0] WLANLDPCDECODERPUNCTUREDBITS — Number of punctured bits per codeword.Calculated as floor(N_punc/N_CW).
  0x18 REPETITIONBITS — WLAN LDPC DECODER REPETITION BITS
    [12:0] WLANLDPCDECODERREPETITIONBITS — Number of repetition bits per codeword.Calculated as floor(N_rep/N_CW).
  0x1C SHORTENEDREM — WLAN LDPC DECODER SHORTENED REM
    [15:0] WLANLDPCDECODERSHORTENEDREM — Number of codewords with one additional shortened bit.Calculated as rem(N_shrt,N_CW).
  0x20 PUNCTUREDREM — WLAN LDPC DECODER PUNCTURED REM
    [15:0] WLANLDPCDECODERPUNCTUREDREM — Number of codewords with one additional punctured bit.Calculated as rem(N_punc,N_CW).
  0x24 REPETITIONREM — WLAN LDPC DECODER REPETITION REM
    [15:0] WLANLDPCDECODERREPETITIONREM — Number of codewords with one additional repetition bit.Calculated as rem(N_rep,N_CW).
  0x28 GENERATEEOP — WLAN LDPC DECODER GENERATE EOP
    [0] WLANLDPCDECODERGENERATEEOP — Generate an EOP flag at the end of the packet:
      values as WLAN_RXP_11B.GENCONTROL.WLANRXP11BGENERATEEOP
  0x2C THRESHOLDDECODER — WLAN LDPC DECODER THRESHOLD DECODER
    [0] WLANLDPCDECODERTHRESHOLDDECODER — Select between LDPC and threshold decoder:
      0=LdpcDecoder; 1=ThresholdDecoder
0x1C000 WIFICORERXTD group — Unspecified
  0x00 RXTDMUXCTRL
    [4] CTRLDIRECTEDRXTD — Enable direct connection between ED and RTMTD in the Vega configuration with new ED, otherwise enable TBus connection.
      0=TbusConnection; 1=DirectConnect
    [3] CTRLDIRECTSCPED — Enable direct connection between SCP and ED in the Vega configuration with new ED, otherwise enable TBus connection.
      0=TbusConnection; 1=DirectConnect
    [2] CTRLDIRECTSCPRXTD — Enable direct connection between SCP and RTMTD of RX11B, otherwise enable TBus connection.
      0=TbusConnection; 1=DirectConnect
    [1] CTRLDIRECTRXTDOUTPUT — Enable direct output of RTMTD or RX11B module, otherwise enable TBus connection.
      0=TbusConnection; 1=DirectConnection
    [0] CTRLRTMTDBYPASS — Bypass the RTMTD module.
      0=NoAction; 1=Bypass
  0x04 RXTDDEBUG
    [1:0] RXTDDEBUG — Enable debug registers RXTD_DEBUG_VALID and RXTD_DEBUG_ENABLE
      values as WLAN_RXP.WLANRXFDDEBUG.WLANRXFDDEBUG
  0x08 RXTDDEBUGVALID ro
    [7:0] RXTDDEBUGVALID — Live state of the valid flow control signals0: SCP Input1: SCP Output2: RTM TD Input3: RTM TD Output4: RX 11B Input5: RX 11B Output6: RX TD OFDM Output7: RX TD DSSS Output
  0x0C RXTDDEBUGENABLE ro
    [7:0] RXTDDEBUGENABLE — Live state of the enable flow control signals0: SCP Input1: SCP Output2: RTM TD Input3: RTM TD Output4: RX 11B Input5: RX 11B Output6: RX TD OFDM Output7: RX TD DSSS Output
  0x10 RXTDCTRL reset 0x5
    [3] RXTDCONFIGRX11B — Select 802.11b RX demodulator.
      0=OfdmDemodulator; 1=80211BDemodulator
    [2] RXTDRXVECTORENABLED — Enable Rx-vector generation.
      values as WLAN_RXP.CONFIG.WLANRXPRXVECTORENABLED
    [1] RXTDDISABLEPHYRESET — Disable automatic PHY reset.
      values as WLAN_RXP.CONFIG.WLANRXPDISABLEPHYRESET
    [0] RXTDCONFIGAUTOMATIC — Enable automatic configuration of the RXTD.
      0=Manual configuration mode; 1=Automatic configuration mode
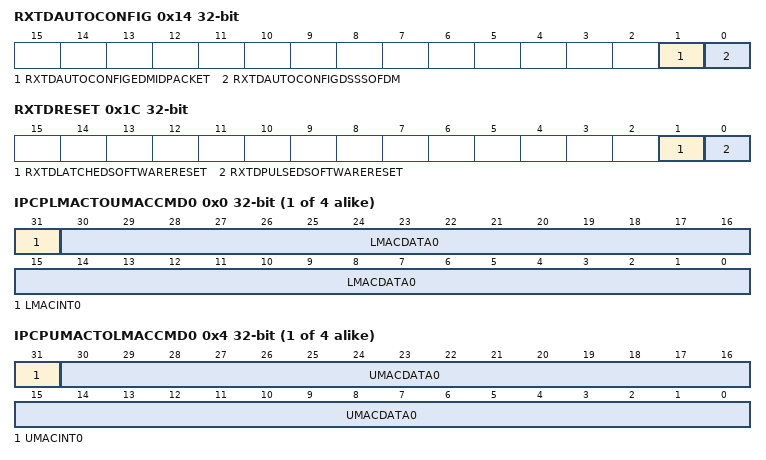
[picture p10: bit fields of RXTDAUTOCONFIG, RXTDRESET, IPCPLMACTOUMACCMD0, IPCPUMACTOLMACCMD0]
  0x14 RXTDAUTOCONFIG
    [1] RXTDAUTOCONFIGEDMIDPACKET — Mid-packet energy detection flag:
      0=DSSS or OFDM packet detected; 1=MidPacketDetected
    [0] RXTDAUTOCONFIGDSSSOFDM — DSSS or OFDM
      0=Dsss; 1=Ofdm
  0x1C RXTDRESET
    [1] RXTDLATCHEDSOFTWARERESET — Latched software reset.
    [0] RXTDPULSEDSOFTWARERESET — Self-clearing software reset.
0x1D000 WIFICOREIPCP_ group — Unspecified
  {0x0+0x18*j} IPCPLMACTOUMACCMD{j} (j=0..3)
    [31] LMACINT{j} — This Read Only bit is set to 1 when the lmac_int_{j} event is asserted.Writing to LMAC_INT_CLR_{j} in the umac_to_lmac_ack_{j} register clears this bit.
    [30:0] LMACDATA{j} — Message data to be passed from the LMAC_{j} to the UMAC_{j}.A write to this register causes lmac_int_{j} to be asserted.
  {0x4+0x18*j} IPCPUMACTOLMACCMD{j} (j=0..3)
    [31] UMACINT{j} — This Read Only bit is set to 1 when umac_int_{j} is asserted.Writing to UMAC_INT_CLR_{j} in the lmac_to_umac_ack_{j} register clears this bit.
    [30:0] UMACDATA{j} — Message data to be passed from the UMAC_{j} to the LMAC_{j}.A write to this register causes the umac_int_{j} interrupt to be asserted.
  {0x8+0x18*j} IPCPLMACTOUMACACK{j} (j=0..3)
    [31] UMACINTCLR{j} — Writing 1 to this bit causes the UMAC_INT_{j} bit in umac_to_lmac_cmd_{j} to be cleared.
  {0xC+0x18*j} IPCPUMACTOLMACACK{j} (j=0..3)
    [31] LMACINTCLR{j} — Writing 1 to this bit causes the LMAC_INT_{j} bit in lmac_to_umac_cmd_{j} to be cleared.
  {0x10+0x18*j} IPCPLMACINTENABLE{j} (j=0..3)
    [31] LMACINTEN{j} — Controls the LMAC_{j} interrupt line (lmac_int_{j}).
      0=The LMAC_{j} interrupt is not enabled; 1=TheLmac{j}InterruptIs1 (The LMAC_{j} interrupt is enabled and the interrupt raised when LMAC_INT_{j}=1)
  {0x14+0x18*j} IPCPUMACINTENABLE{j} (j=0..3)
    [31] UMACINTEN{j} — Controls the UMAC_{j} interrupt line (umac_int_{j}).
      0=The UMAC_{j} interrupt is not enabled; 1=TheUmac{j}InterruptIs1 (The UMAC_{j} interrupt is enabled and the interrupt raised when UMAC_INT_{j}=1)
  0x60 IPCPMVDMAOWNER
    [0] MVDMAOWNER — Software interlock for coordinating ownership of MVDMA peripheral.
      0=MvdmaOwnedByLmac; 1=MvdmaOwnedByUmac
  0x70 LMACWATCHDOGENABLE
    [0] LMACWATCHDOGENABLE — Enable LMAC watchdog. The LMAC watchdog will trigger a reset when the timer reaches zero.
  0x74 LMACWATCHDOGTIMER reset 0xFFFFFFFF
    [31:0] LMACWATCHDOGTIMER — LMAC firmware needs to reinitialise the timer before it reaches zero to prevent the LMAC watchdog triggering a reset.
  0x78 UMACWATCHDOGENABLE
    [0] UMACWATCHDOGENABLE — Enable UMAC watchdog. The UMAC watchdog will trigger a reset when the timer reaches zero.
  0x7C UMACWATCHDOGTIMER reset 0xFFFFFFFF
    [31:0] UMACWATCHDOGTIMER — UMAC firmware needs to reinitialise the timer before it reaches zero to prevent the UMAC watchdog triggering a reset.
